# CMS32M67xx register map
Vendor: CMS; Series: CMS32M67xx; File version: 1.2
ARM 32-bit Cortex-M0+ Microcontroller based device, CPU clock up to 64MHz, etc.
CPU: CM0+ r0p1, little endian, no MPU, no FPU, VTOR, 2 interrupt priority bits
Registers are 32-bit, read-write, reset 0x0 unless marked. A register's access mark holds for its fields unless they carry their own. Offsets are from the block's base; lines under a group give offsets from that group; [hi:lo] are bit positions; {n}, {i} and the like mark numbered series; 'fields as' and 'values as' point back to an identical list; <NAME> marks a mode.

## Memory map
0x00500660 BGR size 0x8 — Temperature Sensor calibration data
0x00500668 TSN size 0x8 — Temperature Sensor calibration data
0x00500894 UID size 0x80 — 128-bit Unique ID
0x20001000 DMAVEC size 0x2C0 — DMA Vector and Control Data Area
0x40005000 DMA size 0x100 — Enhanced DMA Controller
0x40006000 INT size 0x200 — Interrupt Controller
0x4001B000 DBG size 0x100 — DBG Controller
0x40020000 FMC size 0x400 — Flash Memory Controller
0x40020100 SAF size 0x30000 — Flash memory CRC operation function (High-Speed CRC)
0x40020400 CGC size 0x2000 — Clock Generate Control
0x40020404 WDT size 0xC00 — Watchdog Timer with window
0x40020420 RST size 0x40 — Reset Function
0x40020440 LVD size 0x100 — Voltage detector
0x40020D00 DMATRG size 0x100 — Enhanced DMA Controller
0x40040000 PORT size 0x1000 — Port functions
0x40040470 MISC size 0x100 — Miscellaneous function
0x40040FA0 PCBZ size 0x10 — Clock/Buzzer output controller
0x40041A30 IICA size 0x200 — Serial Interface I2C with multimaster and wakeup supported
0x40041D80 TM40 size 0x200 — General Purpose Timer 4
0x400432F0 CRC size 0x100 — General Purpose CRC
0x40044B50 LSITIMER size 0x8
0x40045B38 INTM size 0x100 — Pin input edge detection
0x40061000 TIMER0 size 0xFFF — TIMER0 Decription
0x40061100 TIMER1 size 0xFFF
0x40063000 SSP0 size 0xFFF — SSP0 Decription
0x40064000 UART0 size 0xFFF — UART0 Decription
0x40064100 UART1 size 0xFFF — UART1 Decription
0x40064200 EPWM size 0xFFF — EPWM Decription
0x40064300 CCP size 0xFFF — CCP Decription
0x40064480 DIVSQRT size 0x32
0x400644C0 DIV size 0x32
0x40064500 HALL size 0xF0 — HALL Decription
0x40068000 ADC size 0xFFF — ADC Decription
0x40068200 ACMP size 0xFFF — ACMP Decription
0x40068300 PGA0 size 0x16
0x40068340 ADCLDO size 0x16
0x40068360 DAC size 0x16

## Interrupts
0 LVI (LVD) — Low Voltage detection interrupt
1 INTP0 (INTM) — INTP0 External interrupt request input is valid
2 INTP1 (INTM) — INTP1 External interrupt request input is valid
3 INTP2 (INTM) — INTP2 External interrupt request input is valid
4 INTP3 (INTM) — INTP3 External interrupt request input is valid
5 TM01H (TM40) — TM40 channel 1(higher 8 bit) interrupt request
6 CCP — Capture/PWM IRQ
7 ACMP — ACMP IRQ
8 ADC — ADC IRQ
9 SSP0 — SSP0 IRQ
11 UART0 — UART0 IRQ
12 UART1 — UART1 IRQ
13 EPWM — EPWM IRQ
14 TIMER0 — Timer0 IRQ
15 TIMER1 — Timer1 IRQ
16 IICA — IICA interrupt request
17 LSITIMER — LSI Timer IRQ
19 TM00 (TM40) — TM40 channel 0 interrupt request
20 TM01 (TM40) — TM40 channel 1 interrupt request
21 TM02 (TM40) — TM40 channel 2 interrupt request
22 TM03 (TM40) — TM40 channel 3 interrupt request
31 FMC — Flash erase or write finish

## RST — Reset Function
Base 0x40020420
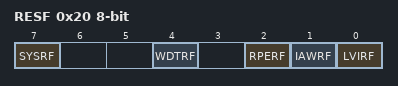
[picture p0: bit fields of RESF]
0x20 RESF 8-bit ro — Reset flag register
  [all] fields
    0=NONE (Internal reset request is not generated, or the RESF register is cleared.); 1=DONE (Internal reset request is generated.)
  [7] SYSRF read-clears — Internal reset request by system reset request(AIRCR.SYSRESETREQ)
  [4] WDTRF read-clears — Internal reset request by watchdog timer(WDT)
  [2] RPERF read-clears — Internal reset request by RAM parity
  [1] IAWRF read-clears — Internal reset request by illegal-memory access
  [0] LVIRF read-clears — Internal reset request by voltage detector

## Licence text in the file
ARM Limited (ARM) is supplying this software for use with Cortex-M processor based microcontroller, but can be equally used for other suitable processor architectures. This file can be freely distributed. Modifications to this file shall be clearly marked. . THIS SOFTWARE IS PROVIDED "AS IS". NO WARRANTIES, WHETHER EXPRESS, IMPLIED. OR STATUTORY, INCLUDING, BUT NOT LIMITED TO, IMPLIED WARRANTIES OF. MERCHANTABILITY AND FITNESS FOR A PARTICULAR PURPOSE APPLY TO THIS SOFTWARE. ARM SHALL NOT, IN ANY CIRCUMSTANCES, BE LIABLE FOR SPECIAL, INCIDENTAL, OR. CONSEQUENTIAL DAMAGES, FOR ANY REASON WHATSOEVER.

## Notices in the file
Copyright (C) 2012-2014 ARM Limited. All rights reserved.
Purpose: System Viewer Description (SVD) Example (Schema Version 1.1)
This is a description of a none-existent and incomplete device
for demonstration purposes only.
Redistribution and use in source and binary forms, with or without
modification, are permitted provided that the following conditions are met:
- Redistributions of source code must retain the above copyright
notice, this list of conditions and the following disclaimer.
- Redistributions in binary form must reproduce the above copyright
notice, this list of conditions and the following disclaimer in the
documentation and/or other materials provided with the distribution.
- Neither the name of ARM nor the names of its contributors may be used
to endorse or promote products derived from this software without
specific prior written permission.
THIS SOFTWARE IS PROVIDED BY THE COPYRIGHT HOLDERS AND CONTRIBUTORS "AS IS"
AND ANY EXPRESS OR IMPLIED WARRANTIES, INCLUDING, BUT NOT LIMITED TO, THE
ARE DISCLAIMED. IN NO EVENT SHALL COPYRIGHT HOLDERS AND CONTRIBUTORS BE
LIABLE FOR ANY DIRECT, INDIRECT, INCIDENTAL, SPECIAL, EXEMPLARY, OR
CONSEQUENTIAL DAMAGES (INCLUDING, BUT NOT LIMITED TO, PROCUREMENT OF
SUBSTITUTE GOODS OR SERVICES; LOSS OF USE, DATA, OR PROFITS; OR BUSINESS
INTERRUPTION) HOWEVER CAUSED AND ON ANY THEORY OF LIABILITY, WHETHER IN
CONTRACT, STRICT LIABILITY, OR TORT (INCLUDING NEGLIGENCE OR OTHERWISE)
ARISING IN ANY WAY OUT OF THE USE OF THIS SOFTWARE, EVEN IF ADVISED OF THE
POSSIBILITY OF SUCH DAMAGE.
